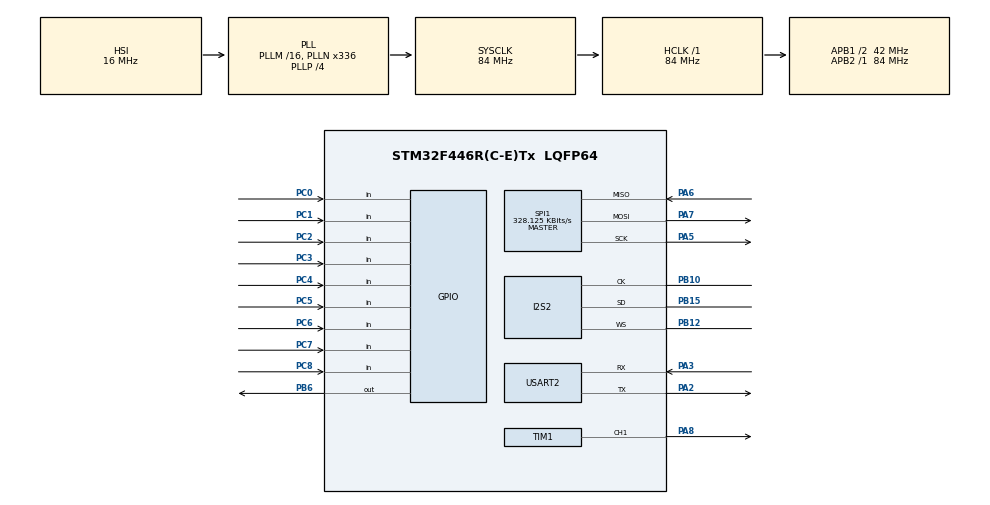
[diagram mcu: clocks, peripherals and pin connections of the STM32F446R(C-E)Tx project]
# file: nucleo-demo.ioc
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Dma.Request0=TIM1_CH1
Dma.Request1=SPI2_TX
Dma.SPI2_TX.1.Direction=DMA_MEMORY_TO_PERIPH
Dma.SPI2_TX.1.FIFOMode=DMA_FIFOMODE_DISABLE
Dma.SPI2_TX.1.Instance=DMA1_Stream4
Dma.SPI2_TX.1.MemDataAlignment=DMA_MDATAALIGN_HALFWORD
Dma.SPI2_TX.1.MemInc=DMA_MINC_ENABLE
Dma.SPI2_TX.1.Mode=DMA_CIRCULAR
Dma.SPI2_TX.1.PeriphDataAlignment=DMA_PDATAALIGN_HALFWORD
Dma.SPI2_TX.1.PeriphInc=DMA_PINC_DISABLE
Dma.SPI2_TX.1.Priority=DMA_PRIORITY_LOW
Dma.TIM1_CH1.0.Direction=DMA_MEMORY_TO_PERIPH
Dma.TIM1_CH1.0.FIFOMode=DMA_FIFOMODE_DISABLE
Dma.TIM1_CH1.0.Instance=DMA2_Stream1
Dma.TIM1_CH1.0.MemDataAlignment=DMA_MDATAALIGN_HALFWORD
Dma.TIM1_CH1.0.MemInc=DMA_MINC_ENABLE
Dma.TIM1_CH1.0.Mode=DMA_NORMAL
Dma.TIM1_CH1.0.PeriphDataAlignment=DMA_PDATAALIGN_HALFWORD
Dma.TIM1_CH1.0.PeriphInc=DMA_PINC_DISABLE
Dma.TIM1_CH1.0.Priority=DMA_PRIORITY_LOW
I2S2.AudioFreq=I2S_AUDIOFREQ_16K
I2S2.ErrorAudioFreq=-0.26 %
I2S2.FullDuplexMode=I2S_FULLDUPLEXMODE_DISABLE
I2S2.Instance=SPI$Index
I2S2.RealAudioFreq=15.957 KHz
I2S2.VirtualMode=I2S_MODE_MASTER
Mcu.Family=STM32F4
Mcu.Name=STM32F446R(C-E)Tx
Mcu.Package=LQFP64
NVIC.DMA1_Stream4_IRQn=true\:0\:5\:false\:false\:true\:false\:true\:true
NVIC.DMA2_Stream1_IRQn=true\:0\:0\:false\:false\:true\:false\:true\:true
NVIC.PriorityGroup=NVIC_PRIORITYGROUP_0
NVIC.TIM2_IRQn=true\:0\:1\:false\:false\:true\:true\:true\:true
PA2.Mode=Asynchronous
PA2.Signal=USART2_TX
PA3.Mode=Asynchronous
PA3.Signal=USART2_RX
PA5.Mode=Full_Duplex_Master
PA5.Signal=SPI1_SCK
PA6.GPIO_PuPd=GPIO_PULLUP
PA6.Mode=Full_Duplex_Master
PA6.Signal=SPI1_MISO
PA7.Mode=Full_Duplex_Master
PA7.Signal=SPI1_MOSI
PA8.Signal=S_TIM1_CH1
PB10.GPIO_PuPd=GPIO_PULLDOWN
PB10.Mode=Half_Duplex_Master
PB10.Signal=I2S2_CK
PB12.GPIO_PuPd=GPIO_PULLDOWN
PB12.Mode=Half_Duplex_Master
PB12.Signal=I2S2_WS
PB15.GPIO_PuPd=GPIO_PULLDOWN
PB15.Mode=Half_Duplex_Master
PB15.Signal=I2S2_SD
PB6.GPIO_PuPd=GPIO_NOPULL
PB6.Signal=GPIO_Output
PC0.GPIO_PuPd=GPIO_PULLUP
PC0.Signal=GPIO_Input
PC1.GPIO_PuPd=GPIO_PULLUP
PC1.Signal=GPIO_Input
PC2.GPIO_PuPd=GPIO_PULLUP
PC2.Signal=GPIO_Input
PC3.GPIO_PuPd=GPIO_PULLUP
PC3.Signal=GPIO_Input
PC4.GPIO_PuPd=GPIO_PULLUP
PC4.Signal=GPIO_Input
PC5.GPIO_PuPd=GPIO_PULLUP
PC5.Signal=GPIO_Input
PC6.GPIO_PuPd=GPIO_PULLUP
PC6.Signal=GPIO_Input
PC7.GPIO_PuPd=GPIO_PULLUP
PC7.Signal=GPIO_Input
PC8.GPIO_PuPd=GPIO_PULLUP
PC8.Signal=GPIO_Input
ProjectManager.HeapSize=0x200
ProjectManager.StackSize=0x400
ProjectManager.TargetToolchain=EWARM V8.50
RCC.AHBFreq_Value=84000000
RCC.APB1CLKDivider=RCC_HCLK_DIV2
RCC.APB1Freq_Value=42000000
RCC.APB1TimFreq_Value=84000000
RCC.APB2Freq_Value=84000000
RCC.APB2TimFreq_Value=84000000
RCC.CortexFreq_Value=84000000
RCC.FLatency-AdvancedSettings=FLASH_LATENCY_2
RCC.HCLKFreq_Value=84000000
RCC.HSE_VALUE=8000000
RCC.HSI_VALUE=16000000
RCC.LSE_VALUE=32768
RCC.PLLN=336
RCC.PLLP=RCC_PLLP_DIV4
RCC.SYSCLKFreq_VALUE=84000000
RCC.SYSCLKSource=RCC_SYSCLKSOURCE_PLLCLK
RCC.USBFreq_Value=168000000
RCC.VCOOutputFreq_Value=336000000
SH.S_TIM1_CH1.0=TIM1_CH1,PWM Generation1 CH1
SPI1.BaudRatePrescaler=SPI_BAUDRATEPRESCALER_256
SPI1.CalculateBaudRate=328.125 KBits/s
SPI1.Direction=SPI_DIRECTION_2LINES
SPI1.Mode=SPI_MODE_MASTER
SPI1.VirtualType=VM_MASTER
TIM1.Channel-PWM\ Generation1\ CH1=TIM_CHANNEL_1
TIM1.CounterMode=TIM_COUNTERMODE_UP
TIM1.Period=105-1
TIM2.AutoReloadPreload=TIM_AUTORELOAD_PRELOAD_DISABLE
TIM2.Channel-Output\ Compare1\ No\ Output=TIM_CHANNEL_1
TIM2.OC1Preload=DISABLE
TIM2.Period=0xffffffff
TIM2.Pulse-Output\ Compare1\ No\ Output=84000
USART2.VirtualMode=VM_ASYNC
VP_TIM1_VS_ClockSourceINT.Mode=Internal
VP_TIM2_VS_ClockSourceINT.Mode=Internal
VP_TIM2_VS_no_output1.Mode=Output Compare1 No Output
board=NUCLEO-F446RE

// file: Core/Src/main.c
/* USER CODE BEGIN Header */
/**
  ******************************************************************************
  * @file           : main.c
  * @brief          : Main program body
  ******************************************************************************
  * @attention
  *
  * Copyright (c) 2026 STMicroelectronics.
  * All rights reserved.
  *
  * This software is licensed under terms that can be found in the LICENSE file
  * in the root directory of this software component.
  * If no LICENSE file comes with this software, it is provided AS-IS.
  *
  ******************************************************************************
  */
/* USER CODE END Header */
#include "main.h"
#include "dma.h"
#include "i2s.h"
#include "spi.h"
#include "tim.h"
#include "usart.h"
#include "gpio.h"

/* USER CODE BEGIN Includes */
//#include "sd.h"
#include <stdint.h>

#include "led.h"
#include "input.h"
#include "dac.h"
#include "sd.h"

/* USER CODE END Includes */

void SystemClock_Config(void);

int main(void)
{

  /* MCU Configuration--------------------------------------------------------*/

  /* Reset of all peripherals, Initializes the Flash interface and the Systick. */
  HAL_Init();

  /* Configure the system clock */
  SystemClock_Config();

  /* Initialize all configured peripherals */
  MX_GPIO_Init();
  MX_DMA_Init();
  MX_SPI1_Init();
  MX_I2S2_Init();
  MX_USART2_UART_Init();
  MX_TIM2_Init();
  MX_TIM1_Init();
  /* USER CODE BEGIN 2 */
  sd_init();
  audio_set_rate(32000);
  audio_init();
  init_input_buffer();

  /* USER CODE END 2 */

  /* Infinite loop */
  /* USER CODE BEGIN WHILE */
  while (1) {
    read_input_buffer();

    /* USER CODE END WHILE */

  }
}

void SystemClock_Config(void)
{
  RCC_OscInitTypeDef RCC_OscInitStruct = {0};
  RCC_ClkInitTypeDef RCC_ClkInitStruct = {0};

  /** Configure the main internal regulator output voltage
  */
  __HAL_RCC_PWR_CLK_ENABLE();
  __HAL_PWR_VOLTAGESCALING_CONFIG(PWR_REGULATOR_VOLTAGE_SCALE3);

  /** Initializes the RCC Oscillators according to the specified parameters
  * in the RCC_OscInitTypeDef structure.
  */
  RCC_OscInitStruct.OscillatorType = RCC_OSCILLATORTYPE_HSI;
  RCC_OscInitStruct.HSIState = RCC_HSI_ON;
  RCC_OscInitStruct.HSICalibrationValue = RCC_HSICALIBRATION_DEFAULT;
  RCC_OscInitStruct.PLL.PLLState = RCC_PLL_ON;
  RCC_OscInitStruct.PLL.PLLSource = RCC_PLLSOURCE_HSI;
  RCC_OscInitStruct.PLL.PLLM = 16;
  RCC_OscInitStruct.PLL.PLLN = 336;
  RCC_OscInitStruct.PLL.PLLP = RCC_PLLP_DIV4;
  RCC_OscInitStruct.PLL.PLLQ = 2;
  RCC_OscInitStruct.PLL.PLLR = 2;
  if (HAL_RCC_OscConfig(&RCC_OscInitStruct) != HAL_OK)
  {
    Error_Handler();
  }

  /** Initializes the CPU, AHB and APB buses clocks
  */
  RCC_ClkInitStruct.ClockType = RCC_CLOCKTYPE_HCLK|RCC_CLOCKTYPE_SYSCLK
                              |RCC_CLOCKTYPE_PCLK1|RCC_CLOCKTYPE_PCLK2;
  RCC_ClkInitStruct.SYSCLKSource = RCC_SYSCLKSOURCE_PLLCLK;
  RCC_ClkInitStruct.AHBCLKDivider = RCC_SYSCLK_DIV1;
  RCC_ClkInitStruct.APB1CLKDivider = RCC_HCLK_DIV2;
  RCC_ClkInitStruct.APB2CLKDivider = RCC_HCLK_DIV1;

  if (HAL_RCC_ClockConfig(&RCC_ClkInitStruct, FLASH_LATENCY_2) != HAL_OK)
  {
    Error_Handler();
  }
}

/* USER CODE BEGIN 4 */
int _write(int fd, char *ptr, int len) {
    HAL_UART_Transmit(&huart2, (uint8_t*)ptr, len, HAL_MAX_DELAY);
    return len;
}

/* USER CODE END 4 */

void Error_Handler(void)
{
  __disable_irq();
  while (1)
  {
  }
}
